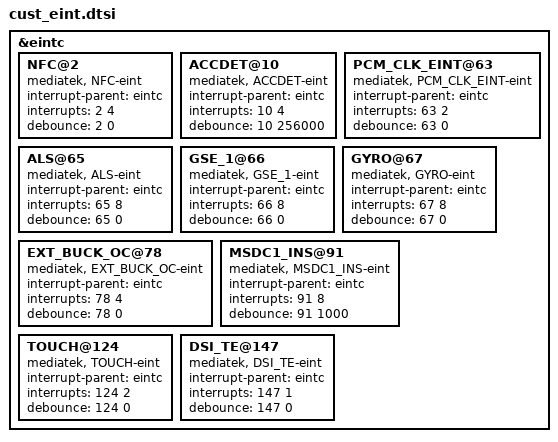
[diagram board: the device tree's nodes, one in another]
/*
 * Generated by MTK SP DrvGen Version 03.13.6 for MT6735. Copyright MediaTek Inc. (C) 2013.
 * Fri Jan 25 14:03:45 2019
 * Do Not Modify the File.
 */

/*************************
 * EINT DTSI File
*************************/

&eintc {
	NFC@2 {
		compatible = "mediatek, NFC-eint";
		interrupt-parent = <&eintc>;
		interrupts = <2 4>;
		debounce = <2 0>;
	};

	ACCDET@10 {
		compatible = "mediatek, ACCDET-eint";
		interrupt-parent = <&eintc>;
		interrupts = <10 4>;
		debounce = <10 256000>;
	};

	PCM_CLK_EINT@63 {
		compatible = "mediatek, PCM_CLK_EINT-eint";
		interrupt-parent = <&eintc>;
		interrupts = <63 2>;
		debounce = <63 0>;
	};

	ALS@65 {
		compatible = "mediatek, ALS-eint";
		interrupt-parent = <&eintc>;
		interrupts = <65 8>;
		debounce = <65 0>;
	};

	GSE_1@66 {
		compatible = "mediatek, GSE_1-eint";
		interrupt-parent = <&eintc>;
		interrupts = <66 8>;
		debounce = <66 0>;
	};

	GYRO@67 {
		compatible = "mediatek, GYRO-eint";
		interrupt-parent = <&eintc>;
		interrupts = <67 8>;
		debounce = <67 0>;
	};

	EXT_BUCK_OC@78 {
		compatible = "mediatek, EXT_BUCK_OC-eint";
		interrupt-parent = <&eintc>;
		interrupts = <78 4>;
		debounce = <78 0>;
	};

	MSDC1_INS@91 {
		compatible = "mediatek, MSDC1_INS-eint";
		interrupt-parent = <&eintc>;
		interrupts = <91 8>;
		debounce = <91 1000>;
	};

	TOUCH@124 {
		compatible = "mediatek, TOUCH-eint";
		interrupt-parent = <&eintc>;
		interrupts = <124 2>;
		debounce = <124 0>;
	};

	DSI_TE@147 {
		compatible = "mediatek, DSI_TE-eint";
		interrupt-parent = <&eintc>;
		interrupts = <147 1>;
		debounce = <147 0>;
	};

};
